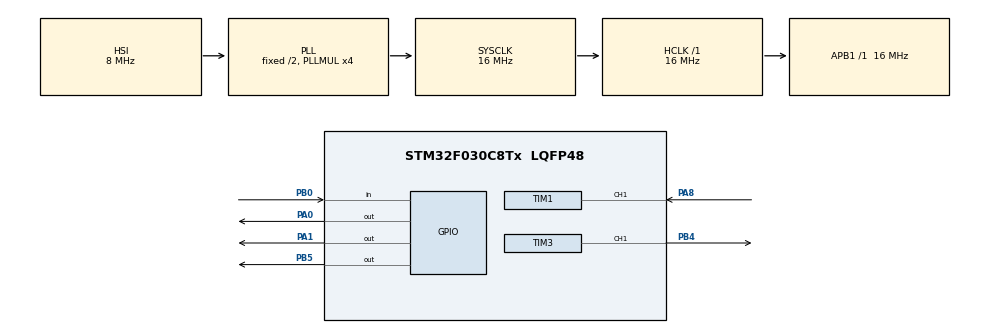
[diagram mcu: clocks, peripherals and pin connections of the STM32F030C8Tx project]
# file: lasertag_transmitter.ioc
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Mcu.Family=STM32F0
Mcu.Name=STM32F030C8Tx
Mcu.Package=LQFP48
NVIC.TIM15_IRQn=true\:0\:0\:false\:false\:true\:true\:true
NVIC.TIM1_BRK_UP_TRG_COM_IRQn=true\:0\:0\:false\:false\:true\:true\:true
NVIC.TIM1_CC_IRQn=true\:0\:0\:false\:false\:true\:true\:true
NVIC.TIM3_IRQn=true\:0\:0\:false\:false\:true\:true\:true
PA0.Signal=GPIO_Output
PA1.Signal=GPIO_Output
PA13.Mode=Serial_Wire
PA13.Signal=SYS_SWDIO
PA14.Mode=Serial_Wire
PA14.Signal=SYS_SWCLK
PA8.GPIO_Speed=GPIO_SPEED_FREQ_HIGH
PA8.Signal=S_TIM1_CH1
PB0.Signal=GPIO_Input
PB4.GPIO_PuPd=GPIO_PULLDOWN
PB4.GPIO_Speed=GPIO_SPEED_FREQ_HIGH
PB4.Signal=S_TIM3_CH1
PB5.Signal=GPIO_Output
ProjectManager.HeapSize=0x200
ProjectManager.StackSize=0x400
ProjectManager.TargetToolchain=STM32CubeIDE
RCC.AHBFreq_Value=16000000
RCC.APB1Freq_Value=16000000
RCC.APB1TimFreq_Value=16000000
RCC.HCLKFreq_Value=16000000
RCC.PLLMUL=RCC_PLL_MUL4
RCC.SYSCLKFreq_VALUE=16000000
RCC.SYSCLKSource=RCC_SYSCLKSOURCE_PLLCLK
SH.S_TIM1_CH1.0=TIM1_CH1,Input_Capture1_from_TI1
SH.S_TIM3_CH1.0=TIM3_CH1,PWM Generation1 CH1
TIM1.AutoReloadPreload=TIM_AUTORELOAD_PRELOAD_ENABLE
TIM1.Channel-Input_Capture1_from_TI1=TIM_CHANNEL_1
TIM1.ICPolarity_CH1=TIM_INPUTCHANNELPOLARITY_RISING
TIM1.Period=419
TIM1.TIM_MasterOutputTrigger=TIM_TRGO_RESET
TIM15.AutoReloadPreload=TIM_AUTORELOAD_PRELOAD_ENABLE
TIM15.Period=9599
TIM3.AutoReloadPreload=TIM_AUTORELOAD_PRELOAD_DISABLE
TIM3.Channel-PWM\ Generation1\ CH1=TIM_CHANNEL_1
TIM3.OCFastMode_PWM-PWM\ Generation1\ CH1=TIM_OCFAST_ENABLE
TIM3.OCMode_PWM-PWM\ Generation1\ CH1=TIM_OCMODE_PWM2
TIM3.Period=419
TIM3.Pulse-PWM\ Generation1\ CH1=210
TIM3.TIM_MasterOutputTrigger=TIM_TRGO_UPDATE
VP_TIM15_VS_ClockSourceINT.Mode=Internal
VP_TIM1_VS_ClockSourceITR.Mode=TriggerSource_ITR2
VP_TIM1_VS_ControllerModeTrigger.Mode=Trigger Mode
board=custom

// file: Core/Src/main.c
/* USER CODE BEGIN Header */
/**
  ******************************************************************************
  * @file           : main.c
  * @brief          : Main program body
  ******************************************************************************
  * @attention
  *
  * <h2><center>&copy; Copyright (c) 2020 STMicroelectronics.
  * All rights reserved.</center></h2>
  *
  * This software component is licensed by ST under BSD 3-Clause license,
  * the "License"; You may not use this file except in compliance with the
  * License. You may obtain a copy of the License at:
  *                        opensource.org/licenses/BSD-3-Clause
  *
  ******************************************************************************
  */
/* USER CODE END Header */

#include "main.h"

TIM_HandleTypeDef htim1;
TIM_HandleTypeDef htim3;
TIM_HandleTypeDef htim15;

void SystemClock_Config(void);
static void MX_GPIO_Init(void);
static void MX_TIM1_Init(void);
static void MX_TIM3_Init(void);
static void MX_TIM15_Init(void);

/* USER CODE BEGIN 0 */
uint8_t lastButton = 1;
/* USER CODE END 0 */

int main(void)
{

  /* MCU Configuration--------------------------------------------------------*/

  /* Reset of all peripherals, Initializes the Flash interface and the Systick. */
  HAL_Init();

  /* Configure the system clock */
  SystemClock_Config();

  /* Initialize all configured peripherals */
  MX_GPIO_Init();
  MX_TIM1_Init();
  MX_TIM3_Init();
  MX_TIM15_Init();

  /* Infinite loop */
  while (1)
  {

    /* USER CODE BEGIN 3 */
	  uint8_t currentButton = HAL_GPIO_ReadPin(GPIOB, GPIO_PIN_0);
	  	  	  	if (lastButton == 1 && currentButton == 0)
	  	  	  	{
//	  	  	  		HAL_GPIO_TogglePin(GPIOA, GPIO_PIN_0);
	  	  	  	send_hex(0x15);

	  	  	  	}
	  	  	lastButton = currentButton;

  }
  /* USER CODE END 3 */
}

void SystemClock_Config(void)
{
  RCC_OscInitTypeDef RCC_OscInitStruct = {0};
  RCC_ClkInitTypeDef RCC_ClkInitStruct = {0};

  /** Initializes the CPU, AHB and APB busses clocks
  */
  RCC_OscInitStruct.OscillatorType = RCC_OSCILLATORTYPE_HSI;
  RCC_OscInitStruct.HSIState = RCC_HSI_ON;
  RCC_OscInitStruct.HSICalibrationValue = RCC_HSICALIBRATION_DEFAULT;
  RCC_OscInitStruct.PLL.PLLState = RCC_PLL_ON;
  RCC_OscInitStruct.PLL.PLLSource = RCC_PLLSOURCE_HSI;
  RCC_OscInitStruct.PLL.PLLMUL = RCC_PLL_MUL4;
  RCC_OscInitStruct.PLL.PREDIV = RCC_PREDIV_DIV1;
  if (HAL_RCC_OscConfig(&RCC_OscInitStruct) != HAL_OK)
  {
    Error_Handler();
  }
  /** Initializes the CPU, AHB and APB busses clocks
  */
  RCC_ClkInitStruct.ClockType = RCC_CLOCKTYPE_HCLK|RCC_CLOCKTYPE_SYSCLK
                              |RCC_CLOCKTYPE_PCLK1;
  RCC_ClkInitStruct.SYSCLKSource = RCC_SYSCLKSOURCE_PLLCLK;
  RCC_ClkInitStruct.AHBCLKDivider = RCC_SYSCLK_DIV1;
  RCC_ClkInitStruct.APB1CLKDivider = RCC_HCLK_DIV1;

  if (HAL_RCC_ClockConfig(&RCC_ClkInitStruct, FLASH_LATENCY_0) != HAL_OK)
  {
    Error_Handler();
  }
}

static void MX_TIM1_Init(void)
{

  TIM_SlaveConfigTypeDef sSlaveConfig = {0};
  TIM_MasterConfigTypeDef sMasterConfig = {0};
  TIM_IC_InitTypeDef sConfigIC = {0};

  htim1.Instance = TIM1;
  htim1.Init.Prescaler = 0;
  htim1.Init.CounterMode = TIM_COUNTERMODE_UP;
  htim1.Init.Period = 419;
  htim1.Init.ClockDivision = TIM_CLOCKDIVISION_DIV1;
  htim1.Init.RepetitionCounter = 0;
  htim1.Init.AutoReloadPreload = TIM_AUTORELOAD_PRELOAD_ENABLE;
  if (HAL_TIM_Base_Init(&htim1) != HAL_OK)
  {
    Error_Handler();
  }
  if (HAL_TIM_IC_Init(&htim1) != HAL_OK)
  {
    Error_Handler();
  }
  sSlaveConfig.SlaveMode = TIM_SLAVEMODE_TRIGGER;
  sSlaveConfig.InputTrigger = TIM_TS_ITR2;
  if (HAL_TIM_SlaveConfigSynchro(&htim1, &sSlaveConfig) != HAL_OK)
  {
    Error_Handler();
  }
  sMasterConfig.MasterOutputTrigger = TIM_TRGO_RESET;
  sMasterConfig.MasterSlaveMode = TIM_MASTERSLAVEMODE_DISABLE;
  if (HAL_TIMEx_MasterConfigSynchronization(&htim1, &sMasterConfig) != HAL_OK)
  {
    Error_Handler();
  }
  sConfigIC.ICPolarity = TIM_INPUTCHANNELPOLARITY_RISING;
  sConfigIC.ICSelection = TIM_ICSELECTION_DIRECTTI;
  sConfigIC.ICPrescaler = TIM_ICPSC_DIV1;
  sConfigIC.ICFilter = 0;
  if (HAL_TIM_IC_ConfigChannel(&htim1, &sConfigIC, TIM_CHANNEL_1) != HAL_OK)
  {
    Error_Handler();
  }

}

static void MX_TIM3_Init(void)
{

  TIM_MasterConfigTypeDef sMasterConfig = {0};
  TIM_OC_InitTypeDef sConfigOC = {0};

  htim3.Instance = TIM3;
  htim3.Init.Prescaler = 0;
  htim3.Init.CounterMode = TIM_COUNTERMODE_UP;
  htim3.Init.Period = 419;
  htim3.Init.ClockDivision = TIM_CLOCKDIVISION_DIV1;
  htim3.Init.AutoReloadPreload = TIM_AUTORELOAD_PRELOAD_DISABLE;
  if (HAL_TIM_PWM_Init(&htim3) != HAL_OK)
  {
    Error_Handler();
  }
  sMasterConfig.MasterOutputTrigger = TIM_TRGO_UPDATE;
  sMasterConfig.MasterSlaveMode = TIM_MASTERSLAVEMODE_DISABLE;
  if (HAL_TIMEx_MasterConfigSynchronization(&htim3, &sMasterConfig) != HAL_OK)
  {
    Error_Handler();
  }
  sConfigOC.OCMode = TIM_OCMODE_PWM2;
  sConfigOC.Pulse = 210;
  sConfigOC.OCPolarity = TIM_OCPOLARITY_HIGH;
  sConfigOC.OCFastMode = TIM_OCFAST_ENABLE;
  if (HAL_TIM_PWM_ConfigChannel(&htim3, &sConfigOC, TIM_CHANNEL_1) != HAL_OK)
  {
    Error_Handler();
  }
  HAL_TIM_MspPostInit(&htim3);

}

static void MX_TIM15_Init(void)
{

  TIM_ClockConfigTypeDef sClockSourceConfig = {0};
  TIM_MasterConfigTypeDef sMasterConfig = {0};

  htim15.Instance = TIM15;
  htim15.Init.Prescaler = 0;
  htim15.Init.CounterMode = TIM_COUNTERMODE_UP;
  htim15.Init.Period = 9599;
  htim15.Init.ClockDivision = TIM_CLOCKDIVISION_DIV1;
  htim15.Init.RepetitionCounter = 0;
  htim15.Init.AutoReloadPreload = TIM_AUTORELOAD_PRELOAD_ENABLE;
  if (HAL_TIM_Base_Init(&htim15) != HAL_OK)
  {
    Error_Handler();
  }
  sClockSourceConfig.ClockSource = TIM_CLOCKSOURCE_INTERNAL;
  if (HAL_TIM_ConfigClockSource(&htim15, &sClockSourceConfig) != HAL_OK)
  {
    Error_Handler();
  }
  sMasterConfig.MasterOutputTrigger = TIM_TRGO_RESET;
  sMasterConfig.MasterSlaveMode = TIM_MASTERSLAVEMODE_DISABLE;
  if (HAL_TIMEx_MasterConfigSynchronization(&htim15, &sMasterConfig) != HAL_OK)
  {
    Error_Handler();
  }

}

static void MX_GPIO_Init(void)
{
  GPIO_InitTypeDef GPIO_InitStruct = {0};

  /* GPIO Ports Clock Enable */
  __HAL_RCC_GPIOA_CLK_ENABLE();
  __HAL_RCC_GPIOB_CLK_ENABLE();

  /*Configure GPIO pin Output Level */
  HAL_GPIO_WritePin(GPIOA, GPIO_PIN_0|GPIO_PIN_1, GPIO_PIN_RESET);

  /*Configure GPIO pin Output Level */
  HAL_GPIO_WritePin(GPIOB, GPIO_PIN_5, GPIO_PIN_RESET);

  /*Configure GPIO pins : PA0 PA1 */
  GPIO_InitStruct.Pin = GPIO_PIN_0|GPIO_PIN_1;
  GPIO_InitStruct.Mode = GPIO_MODE_OUTPUT_PP;
  GPIO_InitStruct.Pull = GPIO_NOPULL;
  GPIO_InitStruct.Speed = GPIO_SPEED_FREQ_LOW;
  HAL_GPIO_Init(GPIOA, &GPIO_InitStruct);

  /*Configure GPIO pin : PB0 */
  GPIO_InitStruct.Pin = GPIO_PIN_0;
  GPIO_InitStruct.Mode = GPIO_MODE_INPUT;
  GPIO_InitStruct.Pull = GPIO_NOPULL;
  HAL_GPIO_Init(GPIOB, &GPIO_InitStruct);

  /*Configure GPIO pin : PB5 */
  GPIO_InitStruct.Pin = GPIO_PIN_5;
  GPIO_InitStruct.Mode = GPIO_MODE_OUTPUT_PP;
  GPIO_InitStruct.Pull = GPIO_NOPULL;
  GPIO_InitStruct.Speed = GPIO_SPEED_FREQ_LOW;
  HAL_GPIO_Init(GPIOB, &GPIO_InitStruct);

}

void Error_Handler(void)
{
}

/************************ (C) COPYRIGHT STMicroelectronics *****END OF FILE****/
